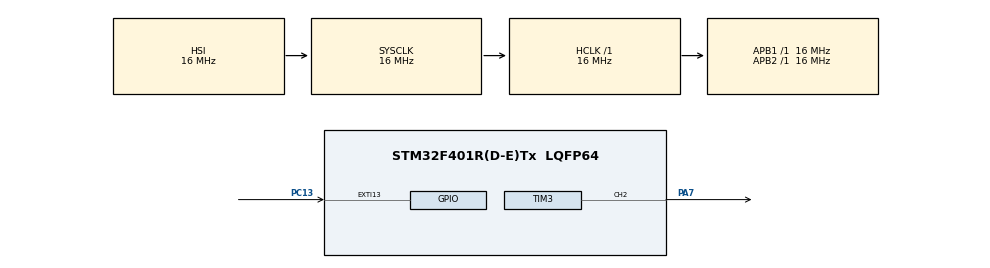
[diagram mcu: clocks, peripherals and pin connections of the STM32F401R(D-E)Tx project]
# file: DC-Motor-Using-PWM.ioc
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Mcu.Family=STM32F4
RCC.CortexFreq_Value=16000000
PC13-ANTI_TAMP.GPIO_PuPd=GPIO_PULLUP
TIM3.AutoReloadPreload=TIM_AUTORELOAD_PRELOAD_ENABLE
ProjectManager.StackSize=0x400
ProjectManager.TargetToolchain=MDK-ARM V5.27
TIM3.Period=1000
RCC.LSE_VALUE=32768
RCC.AHBFreq_Value=16000000
NVIC.EXTI15_10_IRQn=true\:0\:0\:false\:false\:true\:true\:true
SH.S_TIM3_CH2.0=TIM3_CH2,PWM Generation2 CH2
RCC.HSE_VALUE=25000000
board=custom
PC13-ANTI_TAMP.Signal=GPXTI13
RCC.VCOOutputFreq_Value=192000000
RCC.APB2Freq_Value=16000000
VP_TIM2_VS_ClockSourceINT.Mode=Internal
NVIC.TIM2_IRQn=true\:0\:0\:false\:false\:true\:true\:true
TIM2.Period=20
Mcu.Name=STM32F401R(D-E)Tx
RCC.SYSCLKFreq_VALUE=16000000
Mcu.Package=LQFP64
TIM2.Prescaler=16000
PC13-ANTI_TAMP.GPIO_ModeDefaultEXTI=GPIO_MODE_IT_RISING
ProjectManager.HeapSize=0x200
RCC.HSI_VALUE=16000000
NVIC.PriorityGroup=NVIC_PRIORITYGROUP_4
TIM3.Channel-PWM\ Generation2\ CH2=TIM_CHANNEL_2
TIM3.Pulse-PWM\ Generation2\ CH2=500
RCC.APB1Freq_Value=16000000
VP_TIM3_VS_ClockSourceINT.Mode=Internal
PA7.Signal=S_TIM3_CH2

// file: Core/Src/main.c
/* USER CODE BEGIN Header */
/**
  ******************************************************************************
  * @file           : main.c
  * @brief          : Main program body
  ******************************************************************************
  * @attention
  *
  * <h2><center>&copy; Copyright (c) 2020 STMicroelectronics.
  * All rights reserved.</center></h2>
  *
  * This software component is licensed by ST under BSD 3-Clause license,
  * the "License"; You may not use this file except in compliance with the
  * License. You may obtain a copy of the License at:
  *                        opensource.org/licenses/BSD-3-Clause
  *
  ******************************************************************************
  */
/* USER CODE END Header */
#include "main.h"

/* USER CODE BEGIN PD */
void HAL_GPIO_EXTI_Callback(uint16_t GPIO_Pin);
/* USER CODE END PD */

TIM_HandleTypeDef htim2;
TIM_HandleTypeDef htim3;

/* USER CODE BEGIN PV */
uint8_t mode = 0, state = 1;
/* USER CODE END PV */

void SystemClock_Config(void);
static void MX_GPIO_Init(void);
static void MX_TIM3_Init(void);
static void MX_TIM2_Init(void);
/* USER CODE BEGIN PFP */
void HAL_TIM_PeriodElapsedCallback(TIM_HandleTypeDef *htim);
/* USER CODE END PFP */

int main(void)
{

  /* MCU Configuration--------------------------------------------------------*/

  /* Reset of all peripherals, Initializes the Flash interface and the Systick. */
  HAL_Init();

  /* Configure the system clock */
  SystemClock_Config();

  /* Initialize all configured peripherals */
  MX_GPIO_Init();
  MX_TIM3_Init();
  MX_TIM2_Init();
  /* USER CODE BEGIN 2 */
	HAL_TIM_PWM_Start(&htim3, TIM_CHANNEL_2);

  /* USER CODE END 2 */

  /* Infinite loop */
  while (1)
  {

  }
}

void SystemClock_Config(void)
{
  RCC_OscInitTypeDef RCC_OscInitStruct = {0};
  RCC_ClkInitTypeDef RCC_ClkInitStruct = {0};

  /** Configure the main internal regulator output voltage
  */
  __HAL_RCC_PWR_CLK_ENABLE();
  __HAL_PWR_VOLTAGESCALING_CONFIG(PWR_REGULATOR_VOLTAGE_SCALE2);
  /** Initializes the RCC Oscillators according to the specified parameters
  * in the RCC_OscInitTypeDef structure.
  */
  RCC_OscInitStruct.OscillatorType = RCC_OSCILLATORTYPE_HSI;
  RCC_OscInitStruct.HSIState = RCC_HSI_ON;
  RCC_OscInitStruct.HSICalibrationValue = RCC_HSICALIBRATION_DEFAULT;
  RCC_OscInitStruct.PLL.PLLState = RCC_PLL_NONE;
  if (HAL_RCC_OscConfig(&RCC_OscInitStruct) != HAL_OK)
  {
    Error_Handler();
  }
  /** Initializes the CPU, AHB and APB buses clocks
  */
  RCC_ClkInitStruct.ClockType = RCC_CLOCKTYPE_HCLK|RCC_CLOCKTYPE_SYSCLK
                              |RCC_CLOCKTYPE_PCLK1|RCC_CLOCKTYPE_PCLK2;
  RCC_ClkInitStruct.SYSCLKSource = RCC_SYSCLKSOURCE_HSI;
  RCC_ClkInitStruct.AHBCLKDivider = RCC_SYSCLK_DIV1;
  RCC_ClkInitStruct.APB1CLKDivider = RCC_HCLK_DIV1;
  RCC_ClkInitStruct.APB2CLKDivider = RCC_HCLK_DIV1;

  if (HAL_RCC_ClockConfig(&RCC_ClkInitStruct, FLASH_LATENCY_0) != HAL_OK)
  {
    Error_Handler();
  }
}

static void MX_TIM2_Init(void)
{

  TIM_ClockConfigTypeDef sClockSourceConfig = {0};
  TIM_MasterConfigTypeDef sMasterConfig = {0};

  htim2.Instance = TIM2;
  htim2.Init.Prescaler = 16000;
  htim2.Init.CounterMode = TIM_COUNTERMODE_UP;
  htim2.Init.Period = 20;
  htim2.Init.ClockDivision = TIM_CLOCKDIVISION_DIV1;
  htim2.Init.AutoReloadPreload = TIM_AUTORELOAD_PRELOAD_DISABLE;
  if (HAL_TIM_Base_Init(&htim2) != HAL_OK)
  {
    Error_Handler();
  }
  sClockSourceConfig.ClockSource = TIM_CLOCKSOURCE_INTERNAL;
  if (HAL_TIM_ConfigClockSource(&htim2, &sClockSourceConfig) != HAL_OK)
  {
    Error_Handler();
  }
  sMasterConfig.MasterOutputTrigger = TIM_TRGO_RESET;
  sMasterConfig.MasterSlaveMode = TIM_MASTERSLAVEMODE_DISABLE;
  if (HAL_TIMEx_MasterConfigSynchronization(&htim2, &sMasterConfig) != HAL_OK)
  {
    Error_Handler();
  }

}

static void MX_TIM3_Init(void)
{

  TIM_ClockConfigTypeDef sClockSourceConfig = {0};
  TIM_MasterConfigTypeDef sMasterConfig = {0};
  TIM_OC_InitTypeDef sConfigOC = {0};

  htim3.Instance = TIM3;
  htim3.Init.Prescaler = 0;
  htim3.Init.CounterMode = TIM_COUNTERMODE_UP;
  htim3.Init.Period = 1000;
  htim3.Init.ClockDivision = TIM_CLOCKDIVISION_DIV1;
  htim3.Init.AutoReloadPreload = TIM_AUTORELOAD_PRELOAD_ENABLE;
  if (HAL_TIM_Base_Init(&htim3) != HAL_OK)
  {
    Error_Handler();
  }
  sClockSourceConfig.ClockSource = TIM_CLOCKSOURCE_INTERNAL;
  if (HAL_TIM_ConfigClockSource(&htim3, &sClockSourceConfig) != HAL_OK)
  {
    Error_Handler();
  }
  if (HAL_TIM_PWM_Init(&htim3) != HAL_OK)
  {
    Error_Handler();
  }
  sMasterConfig.MasterOutputTrigger = TIM_TRGO_RESET;
  sMasterConfig.MasterSlaveMode = TIM_MASTERSLAVEMODE_DISABLE;
  if (HAL_TIMEx_MasterConfigSynchronization(&htim3, &sMasterConfig) != HAL_OK)
  {
    Error_Handler();
  }
  sConfigOC.OCMode = TIM_OCMODE_PWM1;
  sConfigOC.Pulse = 500;
  sConfigOC.OCPolarity = TIM_OCPOLARITY_HIGH;
  sConfigOC.OCFastMode = TIM_OCFAST_DISABLE;
  if (HAL_TIM_PWM_ConfigChannel(&htim3, &sConfigOC, TIM_CHANNEL_2) != HAL_OK)
  {
    Error_Handler();
  }
  HAL_TIM_MspPostInit(&htim3);

}

static void MX_GPIO_Init(void)
{
  GPIO_InitTypeDef GPIO_InitStruct = {0};

  /* GPIO Ports Clock Enable */
  __HAL_RCC_GPIOC_CLK_ENABLE();
  __HAL_RCC_GPIOA_CLK_ENABLE();

  /*Configure GPIO pin : PC13 */
  GPIO_InitStruct.Pin = GPIO_PIN_13;
  GPIO_InitStruct.Mode = GPIO_MODE_IT_RISING;
  GPIO_InitStruct.Pull = GPIO_PULLUP;
  HAL_GPIO_Init(GPIOC, &GPIO_InitStruct);

  /* EXTI interrupt init*/
  HAL_NVIC_SetPriority(EXTI15_10_IRQn, 0, 0);
  HAL_NVIC_EnableIRQ(EXTI15_10_IRQn);

}

/* USER CODE BEGIN 4 */
void HAL_GPIO_EXTI_Callback(uint16_t GPIO_Pin)
{
	if(GPIO_Pin == GPIO_PIN_13 && state == 1){
		HAL_TIM_Base_Start_IT(&htim2);
		state = 0;
	}
	else{
		__NOP();
	}
}

void HAL_TIM_PeriodElapsedCallback(TIM_HandleTypeDef *htim)
{
	if(htim == &htim2)
	{
		if(HAL_GPIO_ReadPin(GPIOC, GPIO_PIN_13) == GPIO_PIN_RESET)
		{
			++mode;
			mode = mode % 4;
			switch(mode)
			{
				case 0:
						__HAL_TIM_SetCompare(&htim3, TIM_CHANNEL_2, 500);
					break;
				case 1:
						__HAL_TIM_SetCompare(&htim3, TIM_CHANNEL_2, 650);
					break;
				case 2:
						__HAL_TIM_SetCompare(&htim3, TIM_CHANNEL_2, 800);
					break;
				case 3:
						__HAL_TIM_SetCompare(&htim3, TIM_CHANNEL_2, 950);
					break;
			}
			state = 1;
			HAL_TIM_Base_Stop_IT(&htim2);
		}
	}
}
/* USER CODE END 4 */

void Error_Handler(void)
{
}

/************************ (C) COPYRIGHT STMicroelectronics *****END OF FILE****/
